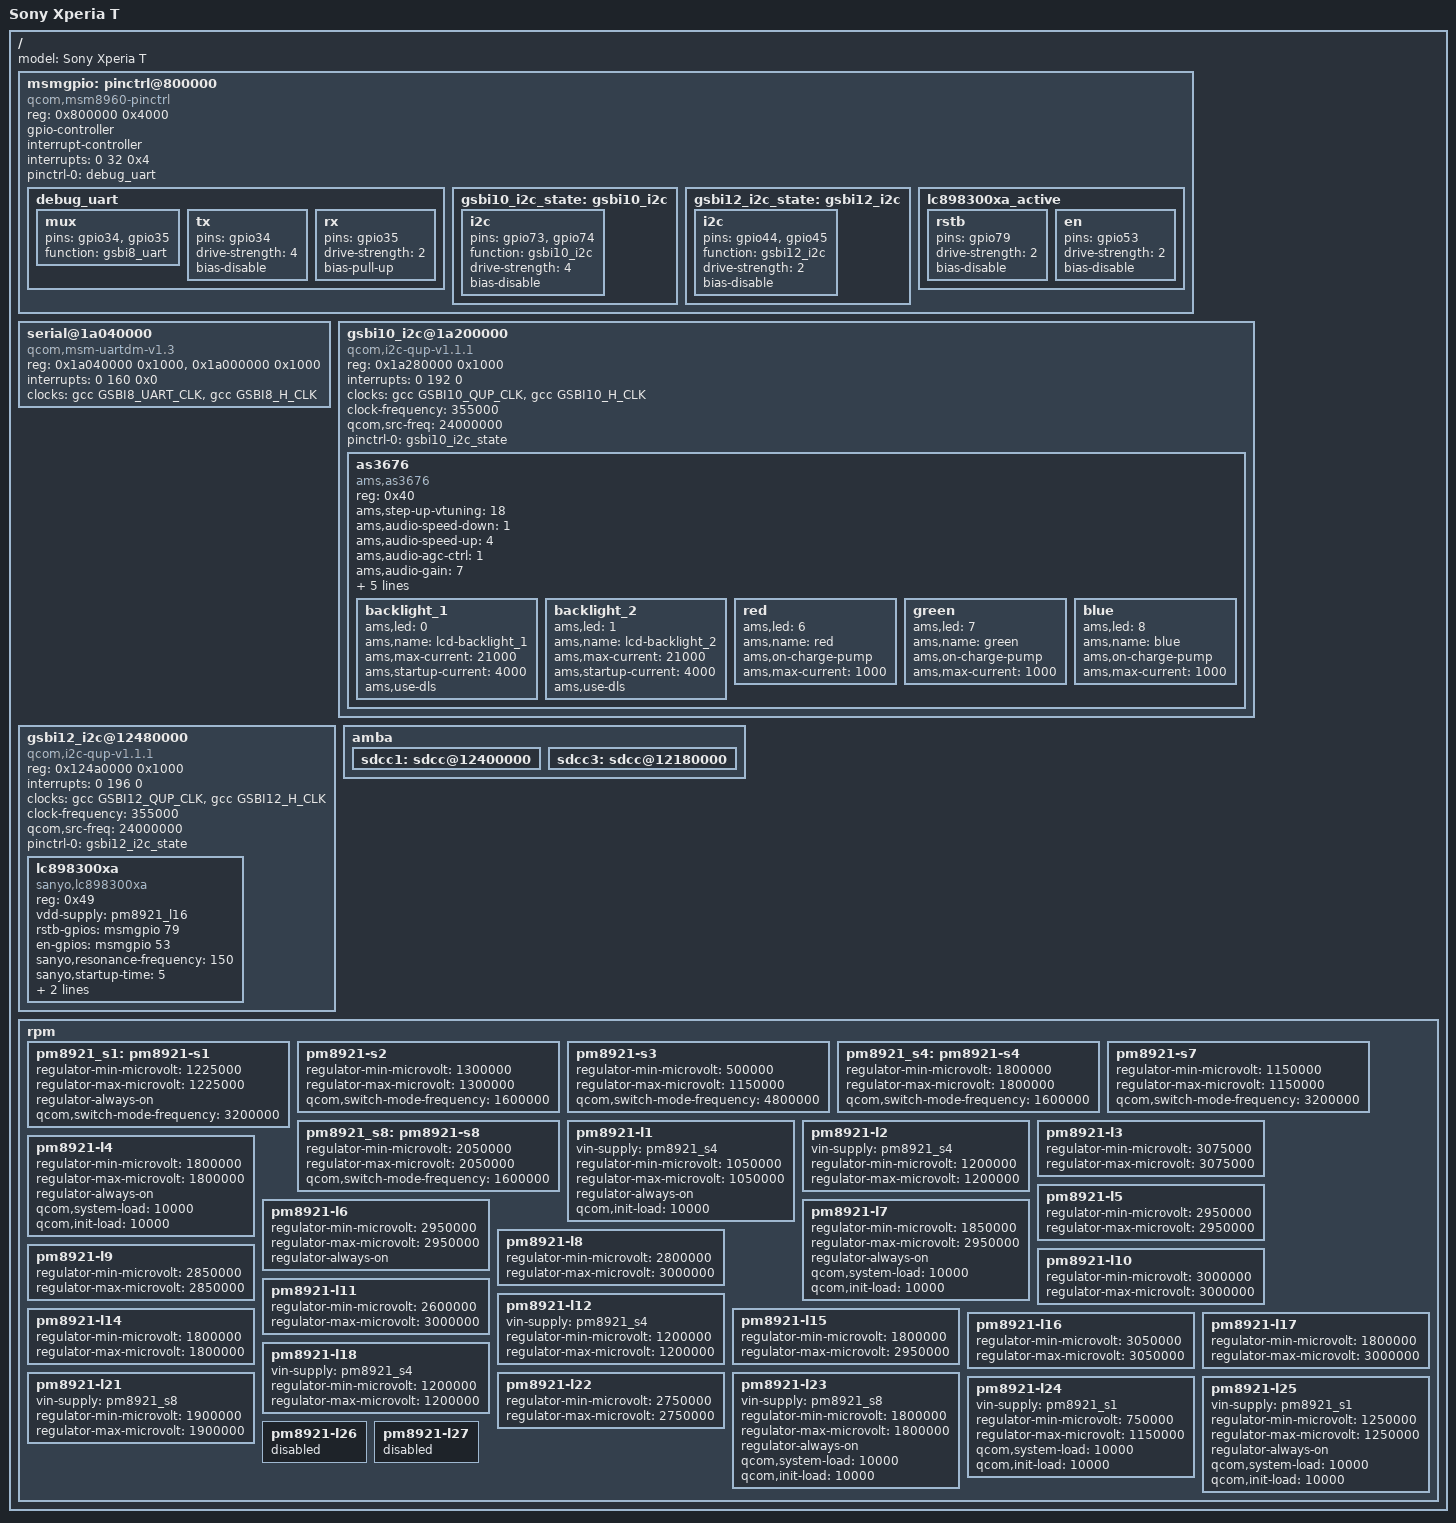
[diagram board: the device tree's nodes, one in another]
#include "qcom-msm8960.dtsi"

/ {
	model = "Sony Xperia T";

	msmgpio: pinctrl@800000 {
		compatible = "qcom,msm8960-pinctrl";
		reg = <0x800000 0x4000>;

		gpio-controller;
		#gpio-cells = <2>;
		interrupt-controller;
		#interrupt-cells = <2>;
		interrupts = <0 32 0x4>;

		pinctrl-names = "default";
		pinctrl-0 = <&debug_uart>;

		debug_uart: debug_uart {
			mux {
				pins = "gpio34", "gpio35";
				function = "gsbi8_uart";
			};

			tx {
				pins = "gpio34";
				drive-strength = <4>;
				bias-disable;
			};

			rx {
				pins = "gpio35";
				drive-strength = <2>;
				bias-pull-up;
			};
		};

		gsbi10_i2c_state: gsbi10_i2c {
			i2c {
				pins = "gpio73", "gpio74";
				function = "gsbi10_i2c";

				drive-strength = <4>;
				bias-disable;
			};
		};

		gsbi12_i2c_state: gsbi12_i2c {
			i2c {
				pins = "gpio44", "gpio45";
				function = "gsbi12_i2c";

				drive-strength = <2>;
				bias-disable;
			};
		};

		lc898300xa_active: lc898300xa_active {
			rstb {
				pins = "gpio79";
				drive-strength = <2>;
				bias-disable;
			};

			en {
				pins = "gpio53";
				drive-strength = <2>;
				bias-disable;
			};
		};
	};

	serial@1a040000 {
		compatible = "qcom,msm-uartdm-v1.3", "qcom,msm-uartdm";
		reg = <0x1a040000 0x1000>,
		      <0x1a000000 0x1000>;
		interrupts = <0 160 0x0>;
		clocks = <&gcc GSBI8_UART_CLK>, <&gcc GSBI8_H_CLK>;
		clock-names = "core", "iface";
	};

	gsbi10_i2c@1a200000 {
		compatible = "qcom,i2c-qup-v1.1.1";
		reg = <0x1a280000 0x1000>;
		interrupts = <0 192 0>;

		clocks = <&gcc GSBI10_QUP_CLK>, <&gcc GSBI10_H_CLK>;
		clock-names = "core", "iface";

		clock-frequency = <355000>;
		qcom,src-freq = <24000000>;

		#address-cells = <1>;
		#size-cells = <0>;

		pinctrl-names = "default";
		pinctrl-0 = <&gsbi10_i2c_state>;

		as3676 {
			compatible = "ams,as3676";
			reg = <0x40>;

			ams,step-up-vtuning = <18>;
			ams,audio-speed-down = <1>;
			ams,audio-speed-up = <4>;
			ams,audio-agc-ctrl = <1>;
			ams,audio-gain = <7>;
			ams,audio-source = <2>;
			ams,step-up-lowcur;
			ams,reset-on-i2c-shutdown;
			ams,caps-mounted-on-dcdc-feedback = <1>;
			ams,cp-control = <0x10>;

			backlight_1 {
				ams,led = <0>;
				ams,name = "lcd-backlight_1";
				ams,max-current = <21000>;
				ams,startup-current = <4000>;
				ams,use-dls;
			};

			backlight_2 {
				ams,led = <1>;
				ams,name = "lcd-backlight_2";
				ams,max-current = <21000>;
				ams,startup-current = <4000>;
				ams,use-dls;
			};

			red {
				ams,led = <6>;
				ams,name = "red";
				ams,on-charge-pump;
				ams,max-current = <1000>;
			};

			green {
				ams,led = <7>;
				ams,name = "green";
				ams,on-charge-pump;
				ams,max-current = <1000>;
			};

			blue {
				ams,led = <8>;
				ams,name = "blue";
				ams,on-charge-pump;
				ams,max-current = <1000>;
			};
		};
	};

	gsbi12_i2c@12480000 {
		compatible = "qcom,i2c-qup-v1.1.1";
		reg = <0x124a0000 0x1000>;
		interrupts = <0 196 0>;

		clocks = <&gcc GSBI12_QUP_CLK>, <&gcc GSBI12_H_CLK>;
		clock-names = "core", "iface";

		clock-frequency = <355000>;
		qcom,src-freq = <24000000>;

		#address-cells = <1>;
		#size-cells = <0>;

		pinctrl-names = "default";
		pinctrl-0 = <&gsbi12_i2c_state>;

		lc898300xa {
			compatible = "sanyo,lc898300xa";
			reg = <0x49>;

			vdd-supply = <&pm8921_l16>;

			rstb-gpios = <&msmgpio 79 0>;
			en-gpios = <&msmgpio 53 0>;

			sanyo,resonance-frequency = <150>;
			sanyo,startup-time = <5>;
			sanyo,break-time = <2>;

			pinctrl-names = "default";
			pinctrl-0 = <&lc898300xa_active>;
		};

	};

	amba {
		sdcc1: sdcc@12400000 {
			status = "okay";
		};

		sdcc3: sdcc@12180000 {
			status = "okay";
		};
	};

	rpm {
		pm8921_s1: pm8921-s1 {
			regulator-min-microvolt = <1225000>;
			regulator-max-microvolt = <1225000>;
			regulator-always-on;

			qcom,switch-mode-frequency = <3200000>;
		};

		pm8921-s2 {
			regulator-min-microvolt = <1300000>;
			regulator-max-microvolt = <1300000>;

			qcom,switch-mode-frequency = <1600000>;
		};

		pm8921-s3 {
			regulator-min-microvolt = <500000>;
			regulator-max-microvolt = <1150000>;

			qcom,switch-mode-frequency = <4800000>;
		};

		pm8921_s4: pm8921-s4 {
			regulator-min-microvolt = <1800000>;
			regulator-max-microvolt = <1800000>;

			qcom,switch-mode-frequency = <1600000>;
		};

		pm8921-s7 {
			regulator-min-microvolt = <1150000>;
			regulator-max-microvolt = <1150000>;

			qcom,switch-mode-frequency = <3200000>;
		};

		pm8921_s8: pm8921-s8 {
			regulator-min-microvolt = <2050000>;
			regulator-max-microvolt = <2050000>;

			qcom,switch-mode-frequency = <1600000>;
		};

		pm8921-l1 {
			vin-supply = <&pm8921_s4>;

			regulator-min-microvolt=<1050000>;
			regulator-max-microvolt = <1050000>;
			regulator-always-on;

			qcom,init-load = <10000>;
		};

		pm8921-l2 {
			vin-supply = <&pm8921_s4>;

			regulator-min-microvolt=<1200000>;
			regulator-max-microvolt = <1200000>;
		};

		pm8921-l3 {
			regulator-min-microvolt=<3075000>;
			regulator-max-microvolt = <3075000>;
		};

		pm8921-l4 {
			regulator-min-microvolt=<1800000>;
			regulator-max-microvolt = <1800000>;
			regulator-always-on;

			qcom,system-load = <10000>;
			qcom,init-load = <10000>;
		};

		pm8921-l5 {
			regulator-min-microvolt=<2950000>;
			regulator-max-microvolt = <2950000>;
		};

		pm8921-l6 {
			regulator-min-microvolt=<2950000>;
			regulator-max-microvolt = <2950000>;
			regulator-always-on;
		};

		pm8921-l7 {
			regulator-min-microvolt=<1850000>;
			regulator-max-microvolt = <2950000>;
			regulator-always-on;

			qcom,system-load = <10000>;
			qcom,init-load = <10000>;
		};

		pm8921-l8 {
			regulator-min-microvolt=<2800000>;
			regulator-max-microvolt = <3000000>;
		};

		pm8921-l9 {
			regulator-min-microvolt=<2850000>;
			regulator-max-microvolt = <2850000>;
		};

		pm8921-l10 {
			regulator-min-microvolt=<3000000>;
			regulator-max-microvolt = <3000000>;
		};

		pm8921-l11 {
			regulator-min-microvolt=<2600000>;
			regulator-max-microvolt = <3000000>;
		};

		pm8921-l12 {
			vin-supply = <&pm8921_s4>;

			regulator-min-microvolt=<1200000>;
			regulator-max-microvolt = <1200000>;
		};

		pm8921-l14 {
			regulator-min-microvolt=<1800000>;
			regulator-max-microvolt = <1800000>;
		};

		pm8921-l15 {
			regulator-min-microvolt=<1800000>;
			regulator-max-microvolt = <2950000>;
		};

		pm8921-l16 {
			regulator-min-microvolt=<3050000>;
			regulator-max-microvolt = <3050000>;
		};

		pm8921-l17 {
			regulator-min-microvolt=<1800000>;
			regulator-max-microvolt = <3000000>;
		};

		pm8921-l18 {
			vin-supply = <&pm8921_s4>;

			regulator-min-microvolt=<1200000>;
			regulator-max-microvolt = <1200000>;
		};

		pm8921-l21 {
			vin-supply = <&pm8921_s8>;

			regulator-min-microvolt=<1900000>;
			regulator-max-microvolt = <1900000>;
		};

		pm8921-l22 {
			regulator-min-microvolt=<2750000>;
			regulator-max-microvolt = <2750000>;
		};

		pm8921-l23 {
			vin-supply = <&pm8921_s8>;

			regulator-min-microvolt=<1800000>;
			regulator-max-microvolt = <1800000>;
			regulator-always-on;

			qcom,system-load = <10000>;
			qcom,init-load = <10000>;
		};

		pm8921-l24 {
			vin-supply = <&pm8921_s1>;

			regulator-min-microvolt=< 750000>;
			regulator-max-microvolt = <1150000>;

			qcom,system-load = <10000>;
			qcom,init-load = <10000>;
		};

		pm8921-l25 {
			vin-supply = <&pm8921_s1>;

			regulator-min-microvolt=<1250000>;
			regulator-max-microvolt = <1250000>;
			regulator-always-on;

			qcom,system-load = <10000>;
			qcom,init-load = <10000>;
		};

		pm8921-l26 {
			status = "disabled";
		};

		pm8921-l27 {
			status = "disabled";
		};
	};
};
